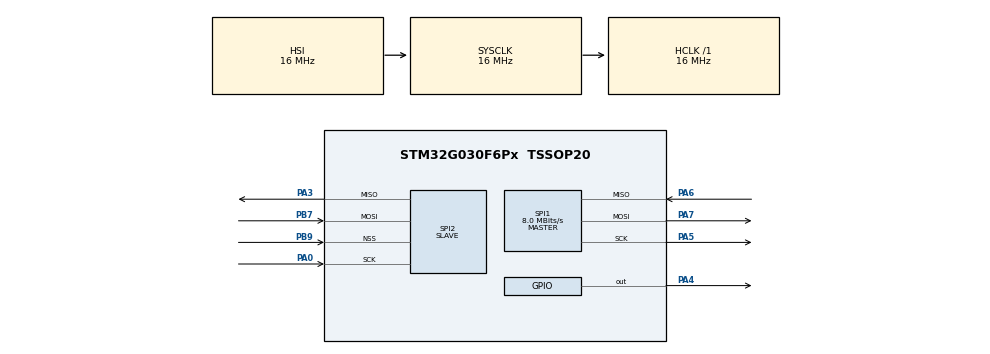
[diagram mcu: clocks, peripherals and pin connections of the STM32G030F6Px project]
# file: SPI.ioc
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Dma.Request0=SPI2_RX
Dma.SPI2_RX.0.Direction=DMA_PERIPH_TO_MEMORY
Dma.SPI2_RX.0.EventEnable=DISABLE
Dma.SPI2_RX.0.Instance=DMA1_Channel1
Dma.SPI2_RX.0.MemDataAlignment=DMA_MDATAALIGN_BYTE
Dma.SPI2_RX.0.MemInc=DMA_MINC_ENABLE
Dma.SPI2_RX.0.Mode=DMA_CIRCULAR
Dma.SPI2_RX.0.PeriphDataAlignment=DMA_PDATAALIGN_BYTE
Dma.SPI2_RX.0.PeriphInc=DMA_PINC_DISABLE
Dma.SPI2_RX.0.Polarity=HAL_DMAMUX_REQ_GEN_RISING
Dma.SPI2_RX.0.Priority=DMA_PRIORITY_LOW
Dma.SPI2_RX.0.RequestNumber=1
Dma.SPI2_RX.0.SignalID=NONE
Dma.SPI2_RX.0.SyncEnable=DISABLE
Dma.SPI2_RX.0.SyncPolarity=HAL_DMAMUX_SYNC_NO_EVENT
Dma.SPI2_RX.0.SyncRequestNumber=1
Dma.SPI2_RX.0.SyncSignalID=NONE
Mcu.Family=STM32G0
Mcu.Name=STM32G030F6Px
Mcu.Package=TSSOP20
NVIC.DMA1_Channel1_IRQn=true\:0\:0\:false\:false\:true\:false\:true\:true
NVIC.SPI1_IRQn=true\:0\:0\:false\:false\:true\:true\:true\:true
NVIC.SPI2_IRQn=true\:0\:0\:false\:false\:true\:true\:true\:true
PA0.Mode=Full_Duplex_Slave
PA0.Signal=SPI2_SCK
PA13.Mode=Serial_Wire
PA13.Signal=SYS_SWDIO
PA14-BOOT0.Mode=Serial_Wire
PA14-BOOT0.Signal=SYS_SWCLK
PA14-BOOT0__PA15.StandardMode=true
PA3.Mode=Full_Duplex_Slave
PA3.Signal=SPI2_MISO
PA4.Signal=GPIO_Output
PA5.Mode=Full_Duplex_Master
PA5.Signal=SPI1_SCK
PA6.Mode=Full_Duplex_Master
PA6.Signal=SPI1_MISO
PA7.Mode=Full_Duplex_Master
PA7.Signal=SPI1_MOSI
PB0__PB1__PB2__PA8.StandardMode=true
PB3__PB4__PB5__PB6.StandardMode=true
PB7.Mode=Full_Duplex_Slave
PB7.Signal=SPI2_MOSI
PB7__PB8.StandardMode=true
PB9.Mode=NSS_Signal_Hard_Input
PB9.Signal=SPI2_NSS
PC14-OSC32_IN\ (PC14)__PB9.StandardMode=true
ProjectManager.HeapSize=0x200
ProjectManager.StackSize=0x400
ProjectManager.TargetToolchain=MDK-ARM V5.32
RCC.AHBFreq_Value=16000000
RCC.CortexFreq_Value=16000000
RCC.EXTERNAL_CLOCK_VALUE=12288000
RCC.HCLKFreq_Value=16000000
RCC.HSE_VALUE=8000000
RCC.HSI_VALUE=16000000
RCC.LSE_VALUE=32768
RCC.SYSCLKFreq_VALUE=16000000
RCC.VCOOutputFreq_Value=128000000
SPI1.CalculateBaudRate=8.0 MBits/s
SPI1.Direction=SPI_DIRECTION_2LINES
SPI1.Mode=SPI_MODE_MASTER
SPI1.VirtualType=VM_MASTER
SPI2.Direction=SPI_DIRECTION_2LINES
SPI2.Mode=SPI_MODE_SLAVE
SPI2.VirtualNSS=VM_NSSHARD
SPI2.VirtualType=VM_SLAVE
board=custom

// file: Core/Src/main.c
/* USER CODE BEGIN Header */
/**
  ******************************************************************************
  * @file           : main.c
  * @brief          : Main program body
  ******************************************************************************
  * @attention
  *
  * Copyright (c) 2026 STMicroelectronics.
  * All rights reserved.
  *
  * This software is licensed under terms that can be found in the LICENSE file
  * in the root directory of this software component.
  * If no LICENSE file comes with this software, it is provided AS-IS.
  *
  ******************************************************************************
  */
/* USER CODE END Header */
#include "main.h"

/* USER CODE BEGIN Includes */
//#define sizeofBuff 20
//uint8_t u8_SPI1_TXBuff[sizeofBuff] = "Master send";
//uint8_t u8_SPI2_RxBuff[sizeofBuff];
//uint8_t Count;

/* USER CODE END Includes */

SPI_HandleTypeDef hspi1;
SPI_HandleTypeDef hspi2;
DMA_HandleTypeDef hdma_spi2_rx;

void SystemClock_Config(void);
static void MX_GPIO_Init(void);
static void MX_DMA_Init(void);
static void MX_SPI1_Init(void);
static void MX_SPI2_Init(void);

uint8_t send_data='A', receive_data=0;
volatile uint32_t count_rx = 0;
/* USER CODE BEGIN PFP */
//void HAL_SPI_RxCpltCallback(SPI_HandleTypeDef *hspi)
//{
  /* Prevent unused argument(s) compilation warning */
  //UNUSED(hspi);
	//if(hspi->Instance == SPI2)
	//{
		//HAL_SPI_Receive_DMA(&hspi2, u8_SPI2_RxBuff,sizeofBuff);
	//}
  /* NOTE : This function should not be modified, when the callback is needed,
            the HAL_SPI_RxCpltCallback should be implemented in the user file
   */
//}
/* USER CODE END PFP */

int main(void)
{

  /* MCU Configuration--------------------------------------------------------*/

  /* Reset of all peripherals, Initializes the Flash interface and the Systick. */
  HAL_Init();

  /* Configure the system clock */
  SystemClock_Config();

  /* Initialize all configured peripherals */
  MX_GPIO_Init();
  MX_DMA_Init();
  MX_SPI1_Init();
  MX_SPI2_Init();
  /* USER CODE BEGIN 2 */
	//HAL_SPI_Receive_DMA(&hspi2, u8_SPI2_RxBuff, sizeofBuff);
	//HAL_GPIO_WritePin(CS_GPIO_Port, CS_Pin, GPIO_PIN_RESET);

	//HAL_SPI_Transmit(&hspi1, u8_SPI1_TXBuff, sizeofBuff, 100);
	//HAL_GPIO_WritePin(CS_GPIO_Port, CS_Pin, GPIO_PIN_SET);
	//HAL_SPI_Transmit_IT(&hspi1, &send_data, 1);

   HAL_SPI_Receive_IT(&hspi2, &receive_data, 1);
  /* USER CODE END 2 */

  /* Infinite loop */
  while (1)
  {
		HAL_GPIO_WritePin(GPIOA, GPIO_PIN_4, GPIO_PIN_SET);
    HAL_SPI_Transmit(&hspi1, &send_data, 1, HAL_MAX_DELAY);
    HAL_GPIO_WritePin(GPIOA, GPIO_PIN_4, GPIO_PIN_RESET);
    send_data++;
    HAL_Delay(1000);
  }
}

/* USER CODE BEGIN Init */
void HAL_SPI_TxCpltCallback(SPI_HandleTypeDef *hspi)
{
  /* Prevent unused argument(s) compilation warning */
  UNUSED(hspi);
	if(hspi->Instance == SPI1)
	{
			HAL_GPIO_WritePin(GPIOA, GPIO_PIN_4, GPIO_PIN_SET);
	}
  /* NOTE : This function should not be modified, when the callback is needed,
            the HAL_SPI_TxCpltCallback should be implemented in the user file
   */
}
 /* USER CODE END Init */

 /* USER CODE BEGIN Init */
void HAL_SPI_RxCpltCallback(SPI_HandleTypeDef *hspi)
{
    if(hspi->Instance == SPI2)
    {
			count_rx++;
      HAL_SPI_Receive_IT(&hspi2, &receive_data, 1);
    }
}
 /* USER CODE END Init */

void SystemClock_Config(void)
{
  RCC_OscInitTypeDef RCC_OscInitStruct = {0};
  RCC_ClkInitTypeDef RCC_ClkInitStruct = {0};

  /** Configure the main internal regulator output voltage
  */
  HAL_PWREx_ControlVoltageScaling(PWR_REGULATOR_VOLTAGE_SCALE1);

  /** Initializes the RCC Oscillators according to the specified parameters
  * in the RCC_OscInitTypeDef structure.
  */
  RCC_OscInitStruct.OscillatorType = RCC_OSCILLATORTYPE_HSI;
  RCC_OscInitStruct.HSIState = RCC_HSI_ON;
  RCC_OscInitStruct.HSIDiv = RCC_HSI_DIV1;
  RCC_OscInitStruct.HSICalibrationValue = RCC_HSICALIBRATION_DEFAULT;
  RCC_OscInitStruct.PLL.PLLState = RCC_PLL_NONE;
  if (HAL_RCC_OscConfig(&RCC_OscInitStruct) != HAL_OK)
  {
    Error_Handler();
  }

  /** Initializes the CPU, AHB and APB buses clocks
  */
  RCC_ClkInitStruct.ClockType = RCC_CLOCKTYPE_HCLK|RCC_CLOCKTYPE_SYSCLK
                              |RCC_CLOCKTYPE_PCLK1;
  RCC_ClkInitStruct.SYSCLKSource = RCC_SYSCLKSOURCE_HSI;
  RCC_ClkInitStruct.AHBCLKDivider = RCC_SYSCLK_DIV1;
  RCC_ClkInitStruct.APB1CLKDivider = RCC_HCLK_DIV1;

  if (HAL_RCC_ClockConfig(&RCC_ClkInitStruct, FLASH_LATENCY_0) != HAL_OK)
  {
    Error_Handler();
  }
}

static void MX_SPI1_Init(void)
{

  /* SPI1 parameter configuration*/
  hspi1.Instance = SPI1;
  hspi1.Init.Mode = SPI_MODE_MASTER;
  hspi1.Init.Direction = SPI_DIRECTION_2LINES;
  hspi1.Init.DataSize = SPI_DATASIZE_8BIT;
  hspi1.Init.CLKPolarity = SPI_POLARITY_LOW;
  hspi1.Init.CLKPhase = SPI_PHASE_1EDGE;
  hspi1.Init.NSS = SPI_NSS_SOFT;
  hspi1.Init.BaudRatePrescaler = SPI_BAUDRATEPRESCALER_2;
  hspi1.Init.FirstBit = SPI_FIRSTBIT_MSB;
  hspi1.Init.TIMode = SPI_TIMODE_DISABLE;
  hspi1.Init.CRCCalculation = SPI_CRCCALCULATION_DISABLE;
  hspi1.Init.CRCPolynomial = 7;
  hspi1.Init.CRCLength = SPI_CRC_LENGTH_DATASIZE;
  hspi1.Init.NSSPMode = SPI_NSS_PULSE_ENABLE;
  if (HAL_SPI_Init(&hspi1) != HAL_OK)
  {
    Error_Handler();
  }

}

static void MX_SPI2_Init(void)
{

  /* SPI2 parameter configuration*/
  hspi2.Instance = SPI2;
  hspi2.Init.Mode = SPI_MODE_SLAVE;
  hspi2.Init.Direction = SPI_DIRECTION_2LINES;
  hspi2.Init.DataSize = SPI_DATASIZE_8BIT;
  hspi2.Init.CLKPolarity = SPI_POLARITY_LOW;
  hspi2.Init.CLKPhase = SPI_PHASE_1EDGE;
  hspi2.Init.NSS = SPI_NSS_HARD_INPUT;
  hspi2.Init.FirstBit = SPI_FIRSTBIT_MSB;
  hspi2.Init.TIMode = SPI_TIMODE_DISABLE;
  hspi2.Init.CRCCalculation = SPI_CRCCALCULATION_DISABLE;
  hspi2.Init.CRCPolynomial = 7;
  hspi2.Init.CRCLength = SPI_CRC_LENGTH_DATASIZE;
  hspi2.Init.NSSPMode = SPI_NSS_PULSE_DISABLE;
  if (HAL_SPI_Init(&hspi2) != HAL_OK)
  {
    Error_Handler();
  }

}

static void MX_DMA_Init(void)
{

  /* DMA controller clock enable */
  __HAL_RCC_DMA1_CLK_ENABLE();

  /* DMA interrupt init */
  /* DMA1_Channel1_IRQn interrupt configuration */
  HAL_NVIC_SetPriority(DMA1_Channel1_IRQn, 0, 0);
  HAL_NVIC_EnableIRQ(DMA1_Channel1_IRQn);

}

static void MX_GPIO_Init(void)
{
  GPIO_InitTypeDef GPIO_InitStruct = {0};

  /* GPIO Ports Clock Enable */
  __HAL_RCC_GPIOB_CLK_ENABLE();
  __HAL_RCC_GPIOA_CLK_ENABLE();

  /*Configure GPIO pin Output Level */
  HAL_GPIO_WritePin(GPIOA, GPIO_PIN_4, GPIO_PIN_RESET);

  /*Configure GPIO pin : PA4 */
  GPIO_InitStruct.Pin = GPIO_PIN_4;
  GPIO_InitStruct.Mode = GPIO_MODE_OUTPUT_PP;
  GPIO_InitStruct.Pull = GPIO_NOPULL;
  GPIO_InitStruct.Speed = GPIO_SPEED_FREQ_LOW;
  HAL_GPIO_Init(GPIOA, &GPIO_InitStruct);

}

void Error_Handler(void)
{
  __disable_irq();
  while (1)
  {
  }
}
